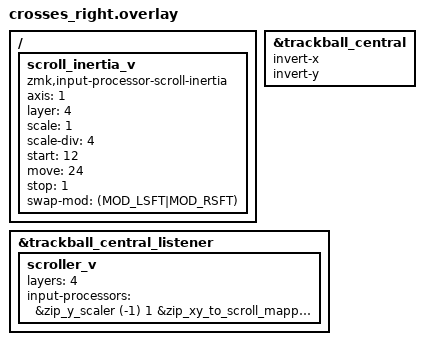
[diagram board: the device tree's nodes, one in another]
#include <dt-bindings/zmk/input_transform.h>
#include <dt-bindings/zmk/modifiers.h>

&trackball_central {
    invert-x;
    invert-y;
};

/ {
    scroll_inertia_v: scroll_inertia_v {
        compatible = "zmk,input-processor-scroll-inertia";
        #input-processor-cells = <0>;
        axis      = <1>;        /* 1 = vertical */
        layer     = <4>;        /* a camada de scroll */
        scale     = <1>;        /* casa com o zip_scroll_scaler abaixo */
        scale-div = <4>;

        /* --- arme facil: inercia dispara com flick suave --- */
        start     = <12>;       /* default 40 -> quanto menor, mais facil arma */
        move      = <24>;       /* default 80 */

        stop      = <1>;
        swap-mod  = <(MOD_LSFT|MOD_RSFT)>;  /* segura Shift = scroll horizontal */
    };
};

&trackball_central_listener {
    scroller_v {
        layers = <4>;
        input-processors = 
            &zip_y_scaler (-1) 1
            &zip_xy_to_scroll_mapper
            &scroll_inertia_v
            &zip_scroll_scaler 1 4
        >;
    };
};
